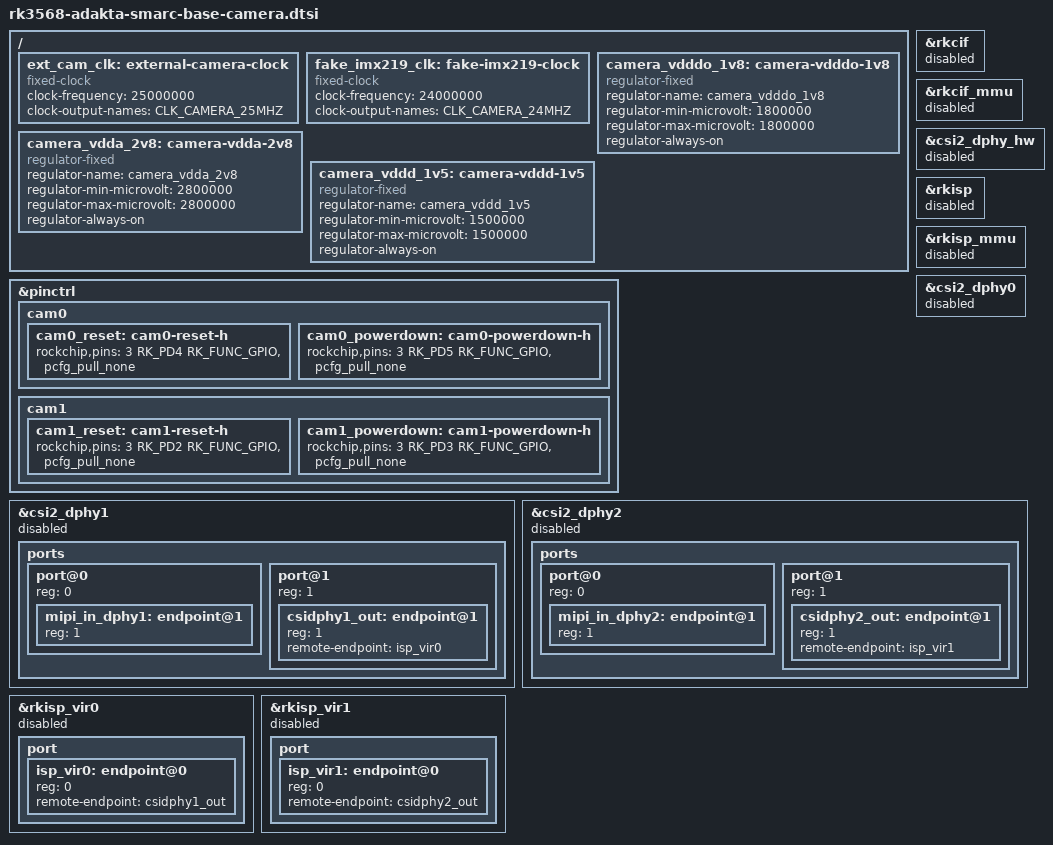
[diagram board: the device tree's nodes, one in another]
// SPDX-License-Identifier: (GPL-2.0+ OR MIT)
/*
 * Copyright (c) 2024 Adakta, Ltd.
 *

 * rkisp --> rkisp_vir0/rkisp0_vir1

 * rkcif_mipi_lvds --> rkcif_mipi_lvds_sditf

 * csi2_dphy0 or (csi2_dphy1、csi2_dphy2)	dphy0

 * mipicamera0 --> csi2_dphy1 --> rkisp_vir0
 * mipicamera1 --> csi2_dphy2 --> rkisp_vir1
 */

/ {
	ext_cam_clk: external-camera-clock {
		compatible = "fixed-clock";
		clock-frequency = <25000000>;
		clock-output-names = "CLK_CAMERA_25MHZ";
		#clock-cells = <0>;
	};

	fake_imx219_clk: fake-imx219-clock {
		compatible = "fixed-clock";
		clock-frequency = <24000000>;
		clock-output-names = "CLK_CAMERA_24MHZ";
		#clock-cells = <0>;
	};

	camera_vdddo_1v8: camera-vdddo-1v8 {
		compatible = "regulator-fixed";
		regulator-name = "camera_vdddo_1v8";
		regulator-min-microvolt = <1800000>;
		regulator-max-microvolt = <1800000>;
		regulator-always-on;
	};

	camera_vdda_2v8: camera-vdda-2v8 {
		compatible = "regulator-fixed";
		regulator-name = "camera_vdda_2v8";
		regulator-min-microvolt = <2800000>;
		regulator-max-microvolt = <2800000>;
		regulator-always-on;
	};

	camera_vddd_1v5: camera-vddd-1v5 {
		compatible = "regulator-fixed";
		regulator-name = "camera_vddd_1v5";
		regulator-min-microvolt = <1500000>;
		regulator-max-microvolt = <1500000>;
		regulator-always-on;
	};
};

&pinctrl {
	cam0 {
		cam0_reset: cam0-reset-h {
			rockchip,pins = <3 RK_PD4 RK_FUNC_GPIO &pcfg_pull_none>;
		};

		cam0_powerdown: cam0-powerdown-h {
			rockchip,pins = <3 RK_PD5 RK_FUNC_GPIO &pcfg_pull_none>;
		};
	};

	cam1 {
		cam1_reset: cam1-reset-h {
			rockchip,pins = <3 RK_PD2 RK_FUNC_GPIO &pcfg_pull_none>;
		};

		cam1_powerdown: cam1-powerdown-h {
			rockchip,pins = <3 RK_PD3 RK_FUNC_GPIO &pcfg_pull_none>;
		};
	};
};

/* must be enabled for any csi2 */
&rkcif {
	status = "disabled";
};

/* must be enabled for any csi2 */
&rkcif_mmu {
	status = "disabled";
};

/* must be enabled for "csi2_dphy0", "csi2_dphy1", "csi2_dphy2" */
&csi2_dphy_hw {
	status = "disabled";
};

/* must be disabled if camera has own ISP */
&rkisp {
	status = "disabled";
};

/* must be disabled if camera has own ISP */
&rkisp_mmu {
	status = "disabled";
};

/* MIPI_CSI_RX_D0/D1/D2/D3/CLK0 */
&csi2_dphy0 {
	status = "disabled";
};

/* MIPI_CSI_RX_D0/D1/CLK0 */
&csi2_dphy1 {
	status = "disabled";
};

/* MIPI_CSI_RX_D2/D3/CLK1 */
&csi2_dphy2 {
	status = "disabled";
};

//**************************************
//*** CAM0 - MIPI_CSI_RX_D0/D1/CLK0 ****
//**************************************

&csi2_dphy1 {
	status = "disabled";

	ports {
		#address-cells = <1>;
		#size-cells = <0>;
		port@0 {
			reg = <0>;
			#address-cells = <1>;
			#size-cells = <0>;

			mipi_in_dphy1: endpoint@1 {
				reg = <1>;
			};
		};
		port@1 {
			reg = <1>;
			#address-cells = <1>;
			#size-cells = <0>;

			csidphy1_out: endpoint@1 {
				reg = <1>;
				remote-endpoint = <&isp_vir0>;
			};
		};
	};
};

&rkisp_vir0 {
	status = "disabled";

	port {
		#address-cells = <1>;
		#size-cells = <0>;

		isp_vir0: endpoint@0 {
			reg = <0>;
			remote-endpoint = <&csidphy1_out>;
		};
	};
};

//**************************************
//*** CAM1 - MIPI_CSI_RX_D2/D3/CLK1 ****
//**************************************

&csi2_dphy2 {
	status = "disabled";

	ports {
		#address-cells = <1>;
		#size-cells = <0>;
		port@0 {
			reg = <0>;
			#address-cells = <1>;
			#size-cells = <0>;

			mipi_in_dphy2: endpoint@1 {
				reg = <1>;
			};
		};
		port@1 {
			reg = <1>;
			#address-cells = <1>;
			#size-cells = <0>;

			csidphy2_out: endpoint@1 {
				reg = <1>;
				remote-endpoint = <&isp_vir1>;
			};
		};
	};
};

&rkisp_vir1 {
	status = "disabled";

	port {
		#address-cells = <1>;
		#size-cells = <0>;

		isp_vir1: endpoint@0 {
			reg = <0>;
			remote-endpoint = <&csidphy2_out>;
		};
	};
};
